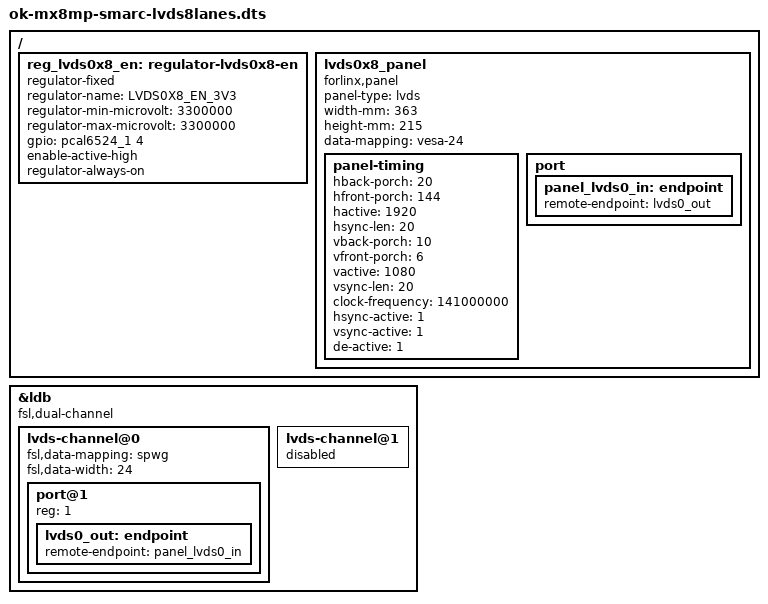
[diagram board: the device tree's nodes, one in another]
/*
 * Copyright 2024 FORLINX
 */

#include "ok-mx8mp-smarc.dts"

/delete-node/ &lvds0_gt928;

/delete-node/ &{/lvds0_panel};
/{
	reg_lvds0x8_en: regulator-lvds0x8-en {
		compatible = "regulator-fixed";
		regulator-name = "LVDS0X8_EN_3V3";
		regulator-min-microvolt = <3300000>;
		regulator-max-microvolt = <3300000>;
		gpio = <&pcal6524_1 4 GPIO_ACTIVE_HIGH>;
		enable-active-high;
		regulator-always-on;
	};

	lvds0x8_panel {
		compatible = "forlinx,panel", "panel-lvds";
		panel-type = "lvds";
		status = "okay";

		width-mm = <363>;
		height-mm = <215>;
		data-mapping = "vesa-24";

		panel-timing {
			hback-porch		= <20>;
			hfront-porch	= <144>;
			hactive			= <1920>;
			hsync-len		= <20>;
			vback-porch		= <10>;
			vfront-porch	= <6>;
			vactive			= <1080>;
			vsync-len		= <20>;
			clock-frequency	= <141000000>;
			hsync-active	= <1>;
			vsync-active	= <1>;
			de-active		= <1>;
		};

		port {
			panel_lvds0_in: endpoint {
				remote-endpoint = <&lvds0_out>;
			};
		};
	};
};

&ldb {
	status = "okay";
	/delete-property/ fsl,duplicate-channel;
	fsl,dual-channel;
	lvds-channel@0 {
		fsl,data-mapping = "spwg";
		fsl,data-width = <24>;
		status = "okay";
		port@1 {
			reg = <1>;

			lvds0_out: endpoint {
				remote-endpoint = <&panel_lvds0_in>;
			};
		};
	};

	lvds-channel@1 {
		status = "disabled";
	};
};
